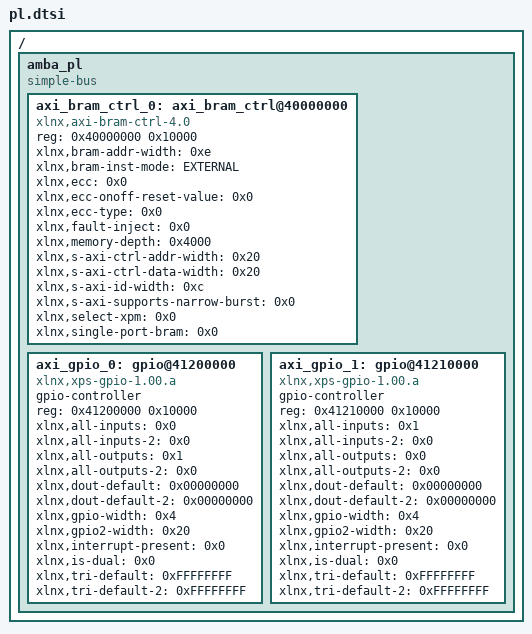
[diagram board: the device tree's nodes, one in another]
/*
 * CAUTION: This file is automatically generated by Xilinx.
 * Version:  
 * Today is: Mon May  8 17:39:17 2017
*/


/ {
	amba_pl: amba_pl {
		#address-cells = <1>;
		#size-cells = <1>;
		compatible = "simple-bus";
		ranges ;
		axi_bram_ctrl_0: axi_bram_ctrl@40000000 {
			compatible = "xlnx,axi-bram-ctrl-4.0";
			reg = <0x40000000 0x10000>;
			xlnx,bram-addr-width = <0xe>;
			xlnx,bram-inst-mode = "EXTERNAL";
			xlnx,ecc = <0x0>;
			xlnx,ecc-onoff-reset-value = <0x0>;
			xlnx,ecc-type = <0x0>;
			xlnx,fault-inject = <0x0>;
			xlnx,memory-depth = <0x4000>;
			xlnx,s-axi-ctrl-addr-width = <0x20>;
			xlnx,s-axi-ctrl-data-width = <0x20>;
			xlnx,s-axi-id-width = <0xc>;
			xlnx,s-axi-supports-narrow-burst = <0x0>;
			xlnx,select-xpm = <0x0>;
			xlnx,single-port-bram = <0x0>;
		};
		axi_gpio_0: gpio@41200000 {
			#gpio-cells = <2>;
			compatible = "xlnx,xps-gpio-1.00.a";
			gpio-controller ;
			reg = <0x41200000 0x10000>;
			xlnx,all-inputs = <0x0>;
			xlnx,all-inputs-2 = <0x0>;
			xlnx,all-outputs = <0x1>;
			xlnx,all-outputs-2 = <0x0>;
			xlnx,dout-default = <0x00000000>;
			xlnx,dout-default-2 = <0x00000000>;
			xlnx,gpio-width = <0x4>;
			xlnx,gpio2-width = <0x20>;
			xlnx,interrupt-present = <0x0>;
			xlnx,is-dual = <0x0>;
			xlnx,tri-default = <0xFFFFFFFF>;
			xlnx,tri-default-2 = <0xFFFFFFFF>;
		};
		axi_gpio_1: gpio@41210000 {
			#gpio-cells = <2>;
			compatible = "xlnx,xps-gpio-1.00.a";
			gpio-controller ;
			reg = <0x41210000 0x10000>;
			xlnx,all-inputs = <0x1>;
			xlnx,all-inputs-2 = <0x0>;
			xlnx,all-outputs = <0x0>;
			xlnx,all-outputs-2 = <0x0>;
			xlnx,dout-default = <0x00000000>;
			xlnx,dout-default-2 = <0x00000000>;
			xlnx,gpio-width = <0x4>;
			xlnx,gpio2-width = <0x20>;
			xlnx,interrupt-present = <0x0>;
			xlnx,is-dual = <0x0>;
			xlnx,tri-default = <0xFFFFFFFF>;
			xlnx,tri-default-2 = <0xFFFFFFFF>;
		};
	};
};
